# NPCX498S register map
File version: 1.0
Registers are 8-bit, read-write, reset 0x0 unless marked. A register's access mark holds for its fields unless they carry their own. Offsets are from the block's base; [hi:lo] are bit positions; {n}, {i} and the like mark numbered series; 'fields as' and 'values as' point back to an identical list.

## ESPI
Base 0x4000A000
0x00 ESPIID 32-bit — eSPI Identification Register (ESPIID)
  [7:0] ID — Host Version ID
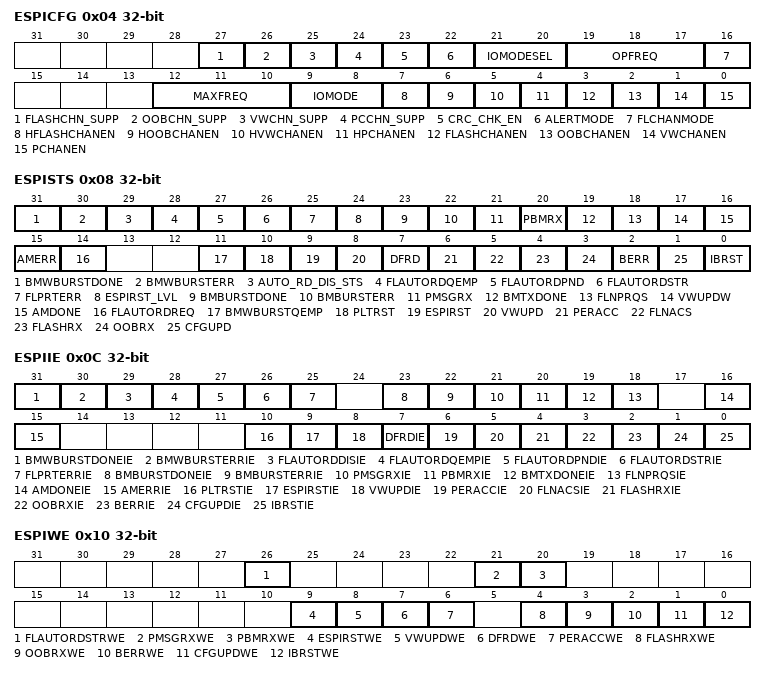
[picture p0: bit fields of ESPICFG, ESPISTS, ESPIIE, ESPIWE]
0x04 ESPICFG 32-bit (reset mask 0xFF) — eSPI Configuration Register (ESPICFG)
  [27] FLASHCHN_SUPP — Flash Access Channel Supported
  [26] OOBCHN_SUPP — OOB Channel Supported
  [25] VWCHN_SUPP — Virtual Wire Channel Supported
  [24] PCCHN_SUPP — Peripheral Channel Supported
  [23] CRC_CHK_EN — CRC Checking Enable
  [22] ALERTMODE
  [21:20] IOMODESEL — I/O Mode Select
  [19:17] OPFREQ — Operating Frequency
  [16] FLCHANMODE — Flash Access Channel Mode
  [12:10] MAXFREQ — Maximum Frequency Supported
  [9:8] IOMODE — I/O mode support
  [7] HFLASHCHANEN — Host Flash Access Channel Enable
  [6] HOOBCHANEN — Host OOB Channel Enable
  [5] HVWCHANEN — Host Virtual Wire Channel Enable
  [4] HPCHANEN — Host Peripheral Channel Enable
  [3] FLASHCHANEN — Core Flash Access Channel Enable
  [2] OOBCHANEN — Core OOB Channel Enable
  [1] VWCHANEN — Core Virtual Wire Channel Enable
  [0] PCHANEN — Core Peripheral Channel Enable
0x08 ESPISTS 32-bit (reset mask 0xFF) — eSPI Status Register (ESPISTS)
  [31] BMWBURSTDONE — Bus Master Burst Mode Write Transfer Done
  [30] BMWBURSTERR — Bus Master Burst Mode Write Transfer Error
  [29] AUTO_RD_DIS_STS — Automatic Read Disable Status
  [28] FLAUTORDQEMP — Flash Automatic Read Queue Empty
  [27] FLAUTORDPND — Flash Automatic Read Request Pending
  [26] FLAUTORDSTR — Flash Automatic Read Request Start
  [25] FLPRTERR — Flash Protection Error
  [24] ESPIRST_LVL — eSPI_RST Level
  [23] BMBURSTDONE — Bus Master Burst Mode Read Transfer Done
  [22] BMBURSTERR — Bus Master Burst Mode Read Transfer Error
  [21] PMSGRX — Peripheral Message Data Received
  [20] PBMRX — Peripheral Bus Master Data Received
  [19] BMTXDONE — Peripheral Bus Master Data Transmitted
  [18] FLNPRQS — Flash Non-Posted Request Sent
  [17] VWUPDW — Virtual Wire Updated Wake-Up
  [16] AMDONE — Automatic Mode Transfer Done
  [15] AMERR — Automatic Mode Transfer Error
  [14] FLAUTORDREQ — Flash Automatic Read Request
  [11] BMWBURSTQEMP — Bus Master Burst Mode Write Queue Empty
  [10] PLTRST — PLTRST Activated
  [9] ESPIRST — eSPI_RST Activated
  [8] VWUPD — Virtual Wire Updated
  [7] DFRD — Peripheral Channel Transaction Deferred
  [6] PERACC — Peripheral Channel Access Detected
  [5] FLNACS — Flash Non-Automatic Completion Sent
  [4] FLASHRX — Flash Data Received
  [3] OOBRX — OOB Data Received
  [2] BERR — eSPI Bus Error
  [1] CFGUPD — eSPI Configuration Updated
  [0] IBRST — In-Band Reset Command Received
0x0C ESPIIE 32-bit (reset mask 0xFF) — eSPI Interrupt Enable Register (ESPIIE)
  [31] BMWBURSTDONEIE — BMWBURSTDONE Interrupt Enable
  [30] BMWBURSTERRIE — BMWRBURSTERR Interrupt Enable
  [29] FLAUTORDDISIE — AUTO_RD_DIS_STS Interrupt Enable
  [28] FLAUTORDQEMPIE — FLAUTORDQEMP Interrupt Enable
  [27] FLAUTORDPNDIE — FLAUTORDPND Interrupt Enable
  [26] FLAUTORDSTRIE — FLAUTORDSTR Interrupt Enable
  [25] FLPRTERRIE — FLPRTERR Interrupt Enable
  [23] BMBURSTDONEIE — BMBURSTDONE Interrupt Enable
  [22] BMBURSTERRIE — BMBURSTERR Interrupt Enable
  [21] PMSGRXIE — PMSGRX Interrupt Enable
  [20] PBMRXIE — PBMRX Interrupt Enable
  [19] BMTXDONEIE — BMTXDONE Interrupt Enable
  [18] FLNPRQSIE — FLNPRQS Interrupt Enable
  [16] AMDONEIE — AMDONE Interrupt Enable
  [15] AMERRIE — AMERR Interrupt Enable
  [10] PLTRSTIE — PLTRST Interrupt Enable
  [9] ESPIRSTIE — eSPI_RST Interrupt Enable
  [8] VWUPDIE — VWUPD Interrupt Enable
  [7] DFRDIE — DFRD Interrupt Enable
  [6] PERACCIE — PERACC Interrupt Enable
  [5] FLNACSIE — FLNACS Interrupt Enable
  [4] FLASHRXIE — FLASHRX Interrupt Enable
  [3] OOBRXIE — OOBRX Interrupt Enable
  [2] BERRIE — BERR Interrupt Enable
  [1] CFGUPDIE — CFGUPD Interrupt Enable
  [0] IBRSTIE — IBRST Interrupt Enable
0x10 ESPIWE 32-bit (reset mask 0xFF) — eSPI Wake-Up Enable Register (ESPIWE)
  [26] FLAUTORDSTRWE — FLAUTORDSTR Wake-Up Enable
  [21] PMSGRXWE — PMSGRX Wake-Up Enable
  [20] PBMRXWE — PBMRX Wake-Up Enable
  [9] ESPIRSTWE — eSPI_RST Wake-Up Enable
  [8] VWUPDWE — VWUPD Wake-Up Enable
  [7] DFRDWE — DFRD Wake-Up Enable
  [6] PERACCWE — PERACC Wake-Up Enable
  [4] FLASHRXWE — FLASHRX Wake-Up Enable
  [3] OOBRXWE — OOBRX Wake-Up Enable
  [2] BERRWE — BERR Wake-Up Enable
  [1] CFGUPDWE — CFGUPD Wake-Up Enable
  [0] IBRSTWE — IBRST Wake-Up Enable
0x14 VWREGIDX 32-bit (reset mask 0xFF) — Virtual Wire Register Index Register (VWREGIDX)
  [11:2] VWREGIDX — Virtual Wire Register Index
0x18 VWREGDATA 32-bit (reset mask 0xFF) — Virtual Wire Register Data Register (VWREGDATA)
0x1C OOBRXRDHEAD 32-bit (reset mask 0xFF) — OOB Receive Buffer Read Head Register (OOBRXRDHEAD)
0x20 OOBTXWRHEAD 32-bit (reset mask 0xFF) — OOB Transmit Buffer Write Head Register (OOBTXWRHEAD)
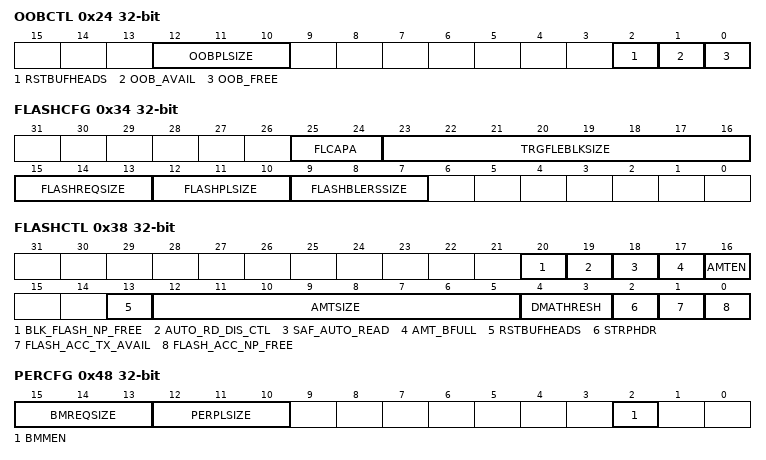
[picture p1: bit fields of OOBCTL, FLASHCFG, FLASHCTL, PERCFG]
0x24 OOBCTL 32-bit (reset mask 0xFF) — OOB Channel Control Register (OOBCTL)
  [12:10] OOBPLSIZE — OOB Channel Maximum Payload Size
  [2] RSTBUFHEADS — Reset Buffer Heads
  [1] OOB_AVAIL — OOB Transmit Queue Available
  [0] OOB_FREE — OOB Receive Queue Free
0x28 FLASHRXRDHEAD 32-bit (reset mask 0xFF) — Flash Receive Buffer Read Head Register (FLASHRXRDHEAD)
0x2C FLASHTXWRHEAD 32-bit (reset mask 0xFF) — Flash Transmit Buffer Write Head Register (FLASHTXWRHEAD)
0x34 FLASHCFG 32-bit (reset mask 0xFF) — Flash Channel Configuration Register (FLASHCFG)
  [25:24] FLCAPA — Flash Sharing Capability Support
  [23:16] TRGFLEBLKSIZE — Target Flash Erase Block Size
  [15:13] FLASHREQSIZE — Flash Access Channel Maximum Read Request Size
  [12:10] FLASHPLSIZE — Flash Access Channel Maximum Payload Size
  [9:7] FLASHBLERSSIZE — Flash Access Channel Block Erase Size
0x38 FLASHCTL 32-bit (reset mask 0xFF) — Flash Channel Control Register (FLASHCTL)
  [20] BLK_FLASH_NP_FREE — Block FLASH_NP_FREE
  [19] AUTO_RD_DIS_CTL — Disable Automatic Read Control
  [18] SAF_AUTO_READ — Target-Attached Flash Automatic Read
  [17] AMT_BFULL — Automatic Mode Receive Buffer Full
  [16] AMTEN — Automatic Mode Enable
  [13] RSTBUFHEADS — Reset Buffer Heads
  [12:5] AMTSIZE — Automatic Mode Transfer Size
  [4:3] DMATHRESH — DMA Request Threshold
  [2] STRPHDR — Strip Header
  [1] FLASH_ACC_TX_AVAIL — Flash Access Transmit Queue Available
  [0] FLASH_ACC_NP_FREE — Flash Access Non-Posted Queue Free
0x3C ESPIERR 32-bit (reset mask 0xFF) — eSPI Error Status Register (ESPIERR)
  [15] UNFLASH — Unsuccessful Flash Completion
  [14] UNPBM — Unsuccessful Bus Master Completion
  [10] VWERR — Virtual Channel Access Error
  [10] EXTRACYC — Extra eSPI Clock Cycles
  [9] UNCMD — Unsupported Command or Cycle Type
  [8] FLBADALN — Target-Attached Flash Bad Address Alignment
  [7] PCBADALN — Posted Peripheral Channel Bad Address Alignment
  [6] NPBADALN — Non-Posted Peripheral Channel Bad Address Alignment
  [5] BADSIZE
  [4] PROTERR — Protocol Error
  [3] ABCOMP — Abnormal Completion
  [2] CRCERR — Transaction CRC Error
  [1] INVCYC — Invalid Cycle Type
  [0] INVCMD — Invalid Command Type
0x40 PBMRXRDHEAD 32-bit (reset mask 0xFF) — Peripheral Bus Master Receive Buffer Read Head Register (PBMRXRDHEAD)
0x44 PBMTXWRHEAD 32-bit (reset mask 0xFF) — Peripheral Bus Master Transmit Buffer Write Head Register (PBMTXWRHEAD)
0x48 PERCFG 32-bit (reset mask 0xFF) — Peripheral Channel Configuration Register (PERCFG)
  [15:13] BMREQSIZE — Peripheral Channel Maximum Read Request Size
  [12:10] PERPLSIZE — Peripheral Channel Maximum Payload Size
  [2] BMMEN — Bus Master Enable
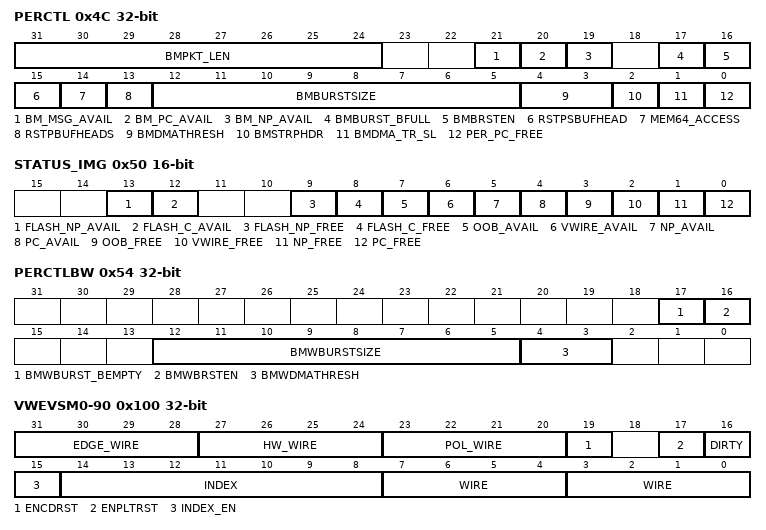
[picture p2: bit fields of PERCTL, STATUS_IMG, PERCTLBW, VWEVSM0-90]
0x4C PERCTL 32-bit (reset mask 0xFF) — Peripheral Channel Control Register (PERCTL)
  [31:24] BMPKT_LEN — Bus Master Packet Length
  [21] BM_MSG_AVAIL — Bus Master Message Available
  [20] BM_PC_AVAIL — Bus Master Posted Available
  [19] BM_NP_AVAIL — Bus Master Non-Posted Available
  [17] BMBURST_BFULL — Bus Master Burst Mode Read Receive Buffer Full
  [16] BMBRSTEN — Bus Master Burst Mode Read Enable
  [15] RSTPSBUFHEAD — Reset Peripheral Target Buffer Head
  [14] MEM64_ACCESS — Memory 64-Bit Access Select
  [13] RSTPBUFHEADS — Reset Peripheral Buffer Heads
  [12:5] BMBURSTSIZE — Bus Master Burst Mode Read Transfer Size
  [4:3] BMDMATHRESH — Read Bus Master DMA Request Threshold
  [2] BMSTRPHDR — Read Bus Master Strip Header
  [1] BMDMA_TR_SL — Bus Master DMA Transmit/Receive Select
  [0] PER_PC_FREE — Peripheral Channel Posted/Completion Receive Queue Free
0x50 STATUS_IMG 16-bit (reset mask 0xFF) — Status Image Register (STATUS_IMG)
  [13] FLASH_NP_AVAIL — Flash Channel Non-Posted Transmit Available
  [12] FLASH_C_AVAIL — Flash Channel Completion Transmit Available
  [9] FLASH_NP_FREE — Flash Channel Non-Posted Receive Free
  [8] FLASH_C_FREE — Flash Channel Completion Receive Available
  [7] OOB_AVAIL — OOB Channel Posted Transmit. Available
  [6] VWIRE_AVAIL — Virtual Wire Channel Transmit Available
  [5] NP_AVAIL — Peripheral Channel Non-Posted Transmit Available
  [4] PC_AVAIL — Peripheral Channel Posted/Completion Transmit. Available
  [3] OOB_FREE — OOB Channel Posted Receive Free
  [2] VWIRE_FREE — Virtual Wire Channel Receive Free
  [1] NP_FREE — Peripheral Channel Non-Posted Receive. Free
  [0] PC_FREE — Peripheral Channel Posted Receive Free
0x54 PERCTLBW 32-bit (reset mask 0xFF) — Peripheral Channel Control for Bus Master Write Register (PERCTLBW)
  [17] BMWBURST_BEMPTY — Bus Master Burst Mode Write Transmit Buffer Empty
  [16] BMWBRSTEN — Bus Master Burst Mode Write Enable
  [12:5] BMWBURSTSIZE — Bus Master Burst Mode Write Transfer Size
  [4:3] BMWDMATHRESH — Bus Master Write DMA Request Threshold
0x58 PSMRXRDHEAD 32-bit (reset mask 0xFF) — Peripheral Target Message Receive Buffer Read Head Register (PSMRXRDHEAD)
0x100 VWEVSM0-90 32-bit (reset mask 0xFF) — Virtual Wire Event Target-to-Controller Register 0-9 (VWEVSM0-9)
  [31:28] EDGE_WIRE 3_0 — Edge Type Wire 3-0
  [27:24] HW_WIRE 3_0 — Hardware-Controlled Wire 3-0
  [23:20] POL_WIRE 3_0 — Polarity of Wire 3-0
  [19] ENCDRST — Enable Core Reset
  [17] ENPLTRST — Enable PLTRST
  [16] DIRTY
  [15] INDEX_EN — Index Enable
  [14:8] INDEX — Index Value
  [7:4] WIRE 3_0 VALID
  [3:0] WIRE 3_0
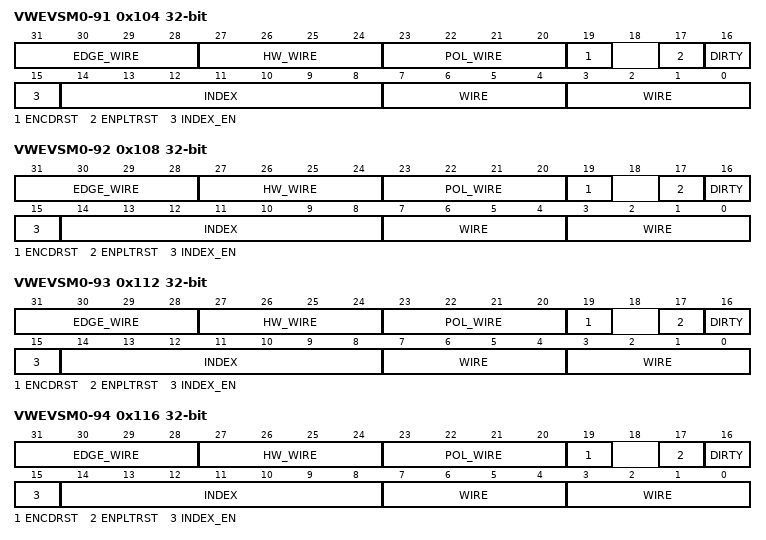
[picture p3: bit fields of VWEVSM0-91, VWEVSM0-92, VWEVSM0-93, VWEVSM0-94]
0x104 VWEVSM0-91 32-bit (reset mask 0xFF) — Virtual Wire Event Target-to-Controller Register 0-9 (VWEVSM0-9)
  fields as VWEVSM0-90
0x108 VWEVSM0-92 32-bit (reset mask 0xFF) — Virtual Wire Event Target-to-Controller Register 0-9 (VWEVSM0-9)
  fields as VWEVSM0-90
0x112 VWEVSM0-93 32-bit (reset mask 0xFF) — Virtual Wire Event Target-to-Controller Register 0-9 (VWEVSM0-9)
  fields as VWEVSM0-90
0x116 VWEVSM0-94 32-bit (reset mask 0xFF) — Virtual Wire Event Target-to-Controller Register 0-9 (VWEVSM0-9)
  fields as VWEVSM0-90
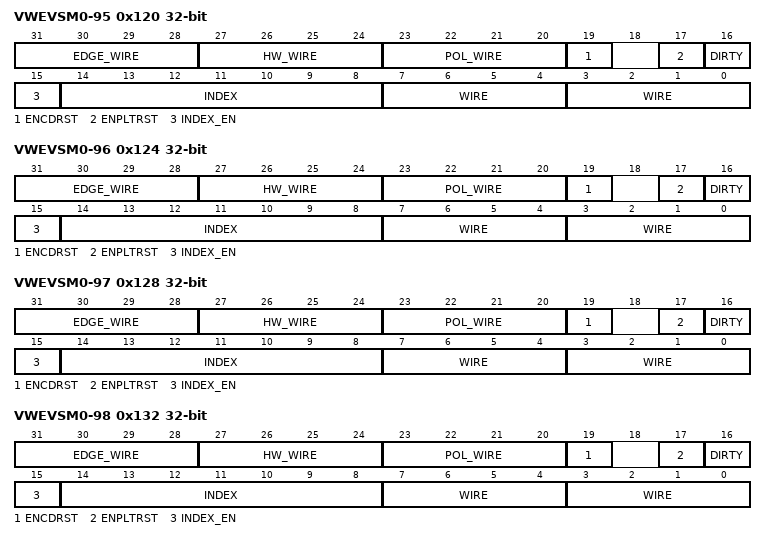
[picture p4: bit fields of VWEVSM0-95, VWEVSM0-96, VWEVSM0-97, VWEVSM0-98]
0x120 VWEVSM0-95 32-bit (reset mask 0xFF) — Virtual Wire Event Target-to-Controller Register 0-9 (VWEVSM0-9)
  fields as VWEVSM0-90
0x124 VWEVSM0-96 32-bit (reset mask 0xFF) — Virtual Wire Event Target-to-Controller Register 0-9 (VWEVSM0-9)
  fields as VWEVSM0-90
0x128 VWEVSM0-97 32-bit (reset mask 0xFF) — Virtual Wire Event Target-to-Controller Register 0-9 (VWEVSM0-9)
  fields as VWEVSM0-90
0x132 VWEVSM0-98 32-bit (reset mask 0xFF) — Virtual Wire Event Target-to-Controller Register 0-9 (VWEVSM0-9)
  fields as VWEVSM0-90
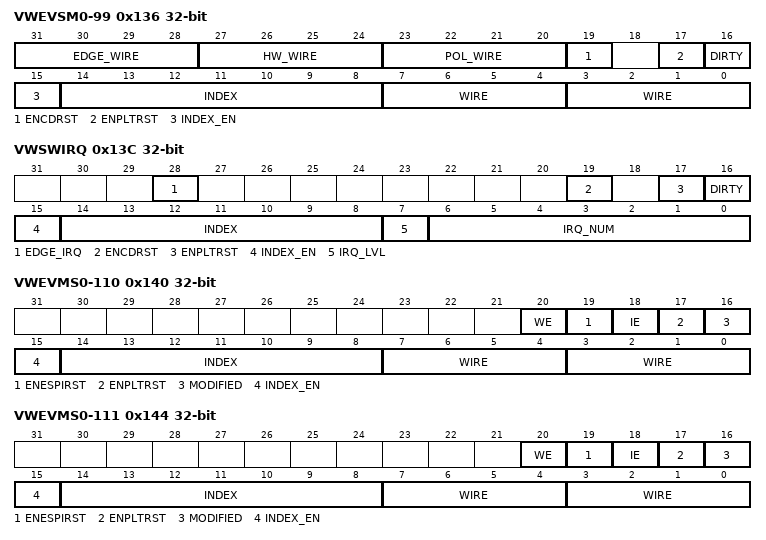
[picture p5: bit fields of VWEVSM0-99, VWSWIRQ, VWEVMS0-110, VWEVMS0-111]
0x136 VWEVSM0-99 32-bit (reset mask 0xFF) — Virtual Wire Event Target-to-Controller Register 0-9 (VWEVSM0-9)
  fields as VWEVSM0-90
0x13C VWSWIRQ 32-bit (reset mask 0xFF) — Virtual Wire Software IRQ Register (VWSWIRQ)
  [28] EDGE_IRQ — Edge Type IRQ
  [19] ENCDRST — Enable Core Reset
  [17] ENPLTRST — Enable PLTRST
  [16] DIRTY
  [15] INDEX_EN — Index Enable
  [14:8] INDEX — Index Value
  [7] IRQ_LVL — IRQ Level
  [6:0] IRQ_NUM — IRQ Number
0x140 VWEVMS0-110 32-bit (reset mask 0xFF) — Virtual Wire Event Controller-to-Target Register 0-11 (VWEVMS0-11)
  [20] WE — Wake-up Enable
  [19] ENESPIRST — Enable eSPI_RST
  [18] IE — Interrupt Enable
  [17] ENPLTRST — Enable PLTRST
  [16] MODIFIED
  [15] INDEX_EN — Index Enable
  [14:8] INDEX — Index Value
  [7:4] WIRE 3_0 VALID
  [3:0] WIRE 3_0
0x144 VWEVMS0-111 32-bit (reset mask 0xFF) — Virtual Wire Event Controller-to-Target Register 0-11 (VWEVMS0-11)
  fields as VWEVMS0-110
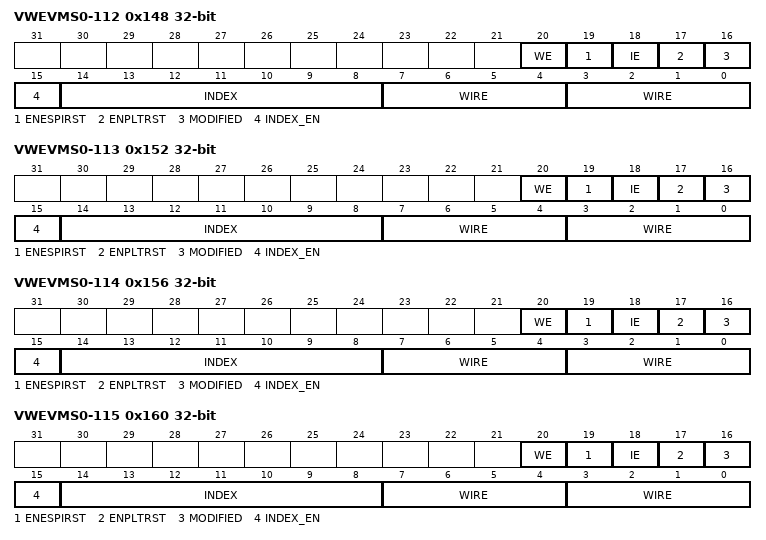
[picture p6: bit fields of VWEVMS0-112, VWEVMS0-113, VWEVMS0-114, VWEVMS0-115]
0x148 VWEVMS0-112 32-bit (reset mask 0xFF) — Virtual Wire Event Controller-to-Target Register 0-11 (VWEVMS0-11)
  fields as VWEVMS0-110
0x152 VWEVMS0-113 32-bit (reset mask 0xFF) — Virtual Wire Event Controller-to-Target Register 0-11 (VWEVMS0-11)
  fields as VWEVMS0-110
0x156 VWEVMS0-114 32-bit (reset mask 0xFF) — Virtual Wire Event Controller-to-Target Register 0-11 (VWEVMS0-11)
  fields as VWEVMS0-110
0x160 VWEVMS0-115 32-bit (reset mask 0xFF) — Virtual Wire Event Controller-to-Target Register 0-11 (VWEVMS0-11)
  fields as VWEVMS0-110
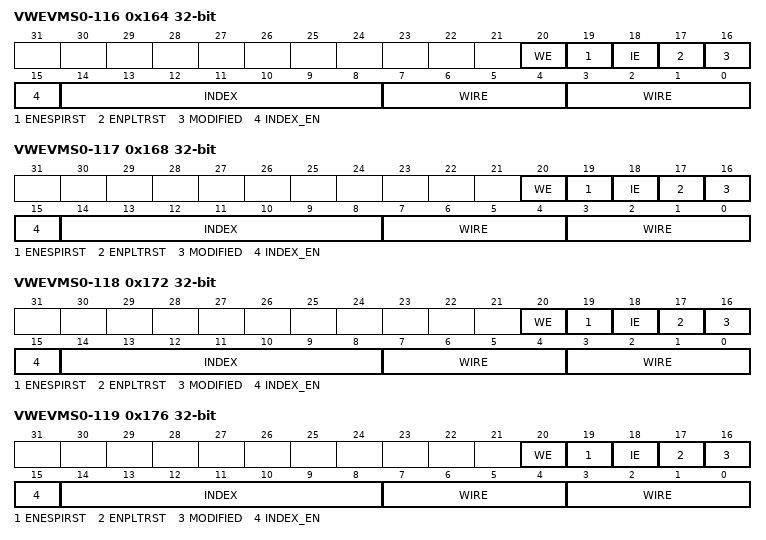
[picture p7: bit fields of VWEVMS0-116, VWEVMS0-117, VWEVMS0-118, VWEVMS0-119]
0x164 VWEVMS0-116 32-bit (reset mask 0xFF) — Virtual Wire Event Controller-to-Target Register 0-11 (VWEVMS0-11)
  fields as VWEVMS0-110
0x168 VWEVMS0-117 32-bit (reset mask 0xFF) — Virtual Wire Event Controller-to-Target Register 0-11 (VWEVMS0-11)
  fields as VWEVMS0-110
0x172 VWEVMS0-118 32-bit (reset mask 0xFF) — Virtual Wire Event Controller-to-Target Register 0-11 (VWEVMS0-11)
  fields as VWEVMS0-110
0x176 VWEVMS0-119 32-bit (reset mask 0xFF) — Virtual Wire Event Controller-to-Target Register 0-11 (VWEVMS0-11)
  fields as VWEVMS0-110
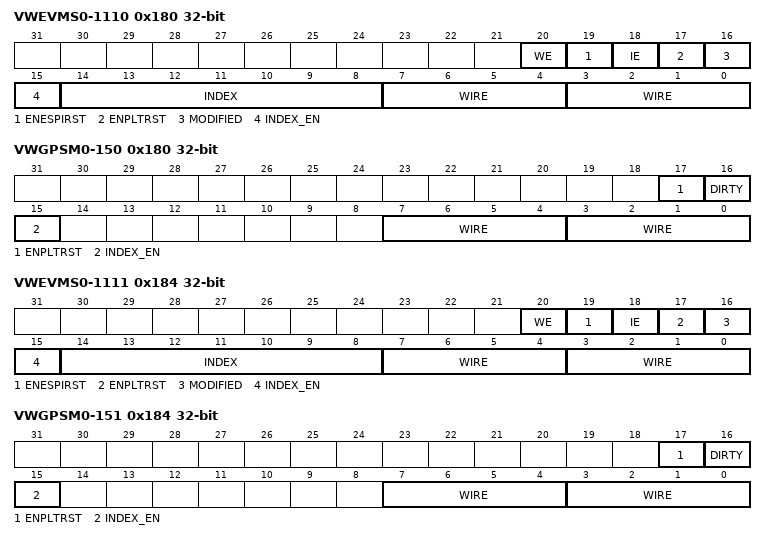
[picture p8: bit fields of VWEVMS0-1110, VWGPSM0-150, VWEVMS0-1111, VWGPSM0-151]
0x180 VWEVMS0-1110 32-bit (reset mask 0xFF) — Virtual Wire Event Controller-to-Target Register 0-11 (VWEVMS0-11)
  fields as VWEVMS0-110
0x180 VWGPSM0-150 32-bit (reset mask 0xFF) — Virtual Wire GPIO Target-to-Controller Register 0-15 (VWGPSM0-15)
  [17] ENPLTRST — Enable PLTRST
  [16] DIRTY
  [15] INDEX_EN — Index Enable
  [7:4] WIRE 3_0 VALID
  [3:0] WIRE 3_0
0x184 VWEVMS0-1111 32-bit (reset mask 0xFF) — Virtual Wire Event Controller-to-Target Register 0-11 (VWEVMS0-11)
  fields as VWEVMS0-110
0x184 VWGPSM0-151 32-bit (reset mask 0xFF) — Virtual Wire GPIO Target-to-Controller Register 0-15 (VWGPSM0-15)
  fields as VWGPSM0-150
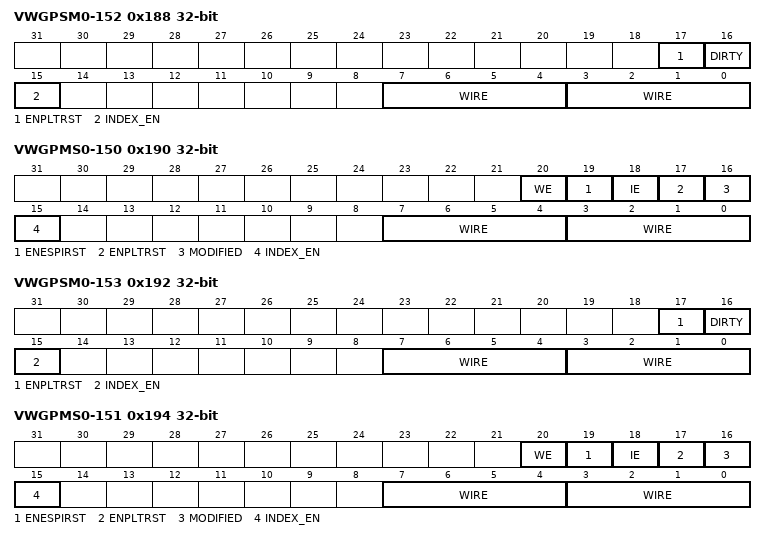
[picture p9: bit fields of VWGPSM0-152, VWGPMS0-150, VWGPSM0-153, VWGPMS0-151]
0x188 VWGPSM0-152 32-bit (reset mask 0xFF) — Virtual Wire GPIO Target-to-Controller Register 0-15 (VWGPSM0-15)
  fields as VWGPSM0-150
0x190 VWGPMS0-150 32-bit (reset mask 0xFF) — Virtual Wire GPIO Controller-to-Target Register 0-15 (VWGPMS0-15)
  [20] WE — Wake-up Enable
  [19] ENESPIRST — Enable eSPI_RST
  [18] IE — Interrupt Enable
  [17] ENPLTRST — Enable PLTRST
  [16] MODIFIED
  [15] INDEX_EN — Index Enable
  [7:4] WIRE 3_0 VALID
  [3:0] WIRE 3_0
0x192 VWGPSM0-153 32-bit (reset mask 0xFF) — Virtual Wire GPIO Target-to-Controller Register 0-15 (VWGPSM0-15)
  fields as VWGPSM0-150
0x194 VWGPMS0-151 32-bit (reset mask 0xFF) — Virtual Wire GPIO Controller-to-Target Register 0-15 (VWGPMS0-15)
  fields as VWGPMS0-150
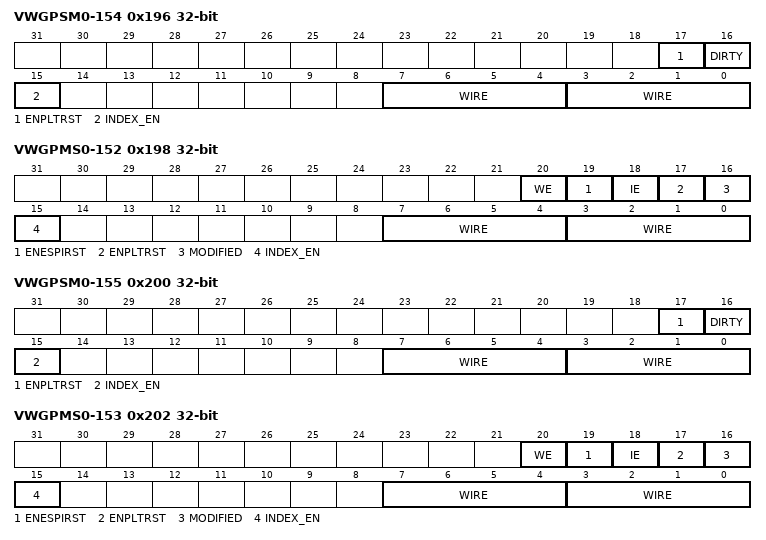
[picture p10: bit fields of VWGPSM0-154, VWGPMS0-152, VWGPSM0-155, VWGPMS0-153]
0x196 VWGPSM0-154 32-bit (reset mask 0xFF) — Virtual Wire GPIO Target-to-Controller Register 0-15 (VWGPSM0-15)
  fields as VWGPSM0-150
0x198 VWGPMS0-152 32-bit (reset mask 0xFF) — Virtual Wire GPIO Controller-to-Target Register 0-15 (VWGPMS0-15)
  fields as VWGPMS0-150
0x200 VWGPSM0-155 32-bit (reset mask 0xFF) — Virtual Wire GPIO Target-to-Controller Register 0-15 (VWGPSM0-15)
  fields as VWGPSM0-150
0x202 VWGPMS0-153 32-bit (reset mask 0xFF) — Virtual Wire GPIO Controller-to-Target Register 0-15 (VWGPMS0-15)
  fields as VWGPMS0-150
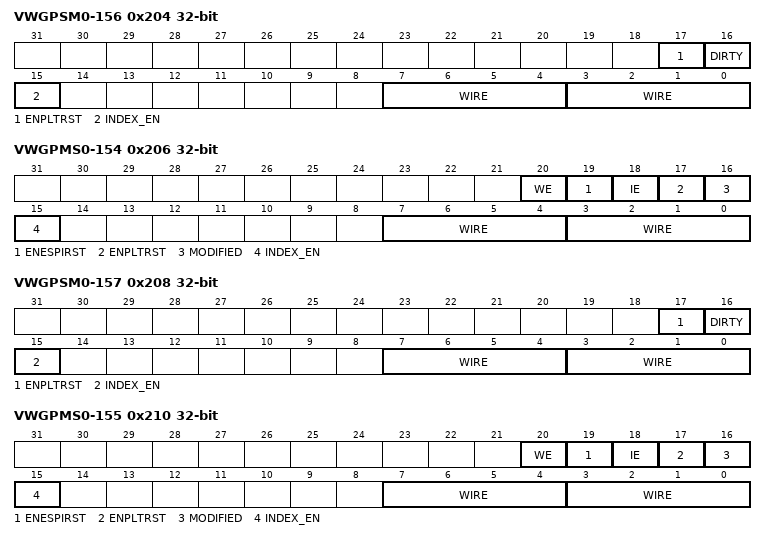
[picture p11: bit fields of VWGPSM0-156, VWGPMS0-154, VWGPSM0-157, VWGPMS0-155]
0x204 VWGPSM0-156 32-bit (reset mask 0xFF) — Virtual Wire GPIO Target-to-Controller Register 0-15 (VWGPSM0-15)
  fields as VWGPSM0-150
0x206 VWGPMS0-154 32-bit (reset mask 0xFF) — Virtual Wire GPIO Controller-to-Target Register 0-15 (VWGPMS0-15)
  fields as VWGPMS0-150
0x208 VWGPSM0-157 32-bit (reset mask 0xFF) — Virtual Wire GPIO Target-to-Controller Register 0-15 (VWGPSM0-15)
  fields as VWGPSM0-150
0x210 VWGPMS0-155 32-bit (reset mask 0xFF) — Virtual Wire GPIO Controller-to-Target Register 0-15 (VWGPMS0-15)
  fields as VWGPMS0-150
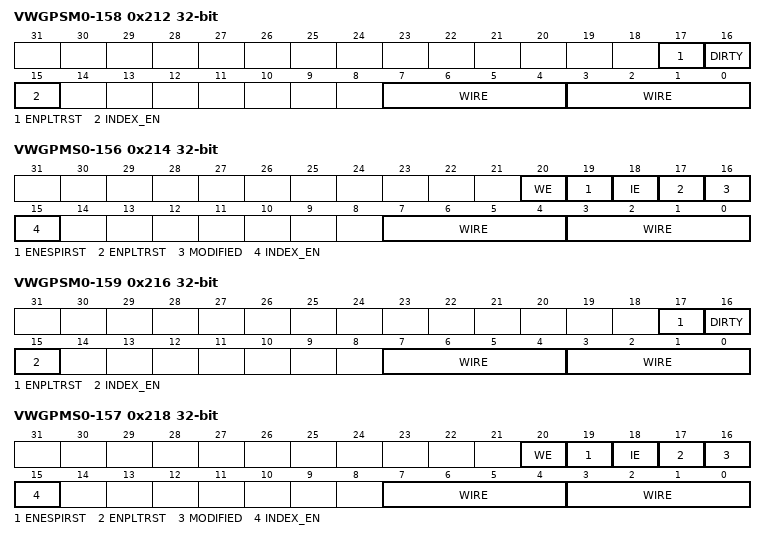
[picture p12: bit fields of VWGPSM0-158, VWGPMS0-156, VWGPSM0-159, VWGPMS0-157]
0x212 VWGPSM0-158 32-bit (reset mask 0xFF) — Virtual Wire GPIO Target-to-Controller Register 0-15 (VWGPSM0-15)
  fields as VWGPSM0-150
0x214 VWGPMS0-156 32-bit (reset mask 0xFF) — Virtual Wire GPIO Controller-to-Target Register 0-15 (VWGPMS0-15)
  fields as VWGPMS0-150
0x216 VWGPSM0-159 32-bit (reset mask 0xFF) — Virtual Wire GPIO Target-to-Controller Register 0-15 (VWGPSM0-15)
  fields as VWGPSM0-150
0x218 VWGPMS0-157 32-bit (reset mask 0xFF) — Virtual Wire GPIO Controller-to-Target Register 0-15 (VWGPMS0-15)
  fields as VWGPMS0-150
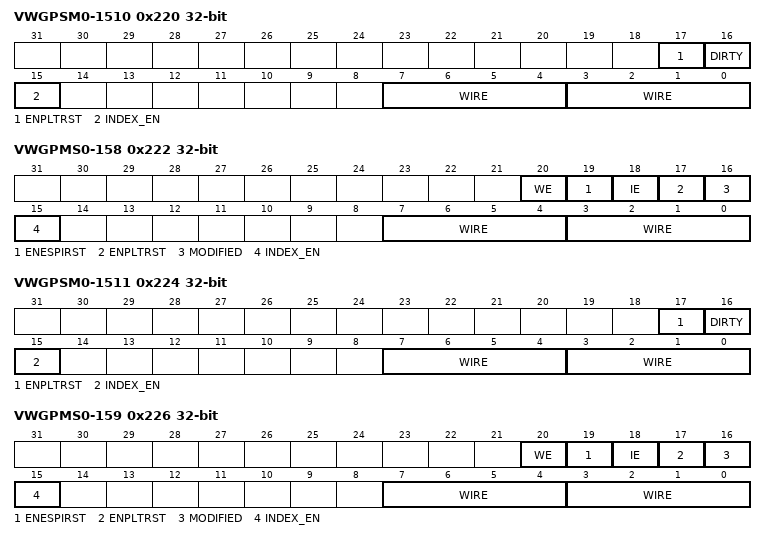
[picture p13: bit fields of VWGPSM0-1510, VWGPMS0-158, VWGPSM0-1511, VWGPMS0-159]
0x220 VWGPSM0-1510 32-bit (reset mask 0xFF) — Virtual Wire GPIO Target-to-Controller Register 0-15 (VWGPSM0-15)
  fields as VWGPSM0-150
0x222 VWGPMS0-158 32-bit (reset mask 0xFF) — Virtual Wire GPIO Controller-to-Target Register 0-15 (VWGPMS0-15)
  fields as VWGPMS0-150
0x224 VWGPSM0-1511 32-bit (reset mask 0xFF) — Virtual Wire GPIO Target-to-Controller Register 0-15 (VWGPSM0-15)
  fields as VWGPSM0-150
0x226 VWGPMS0-159 32-bit (reset mask 0xFF) — Virtual Wire GPIO Controller-to-Target Register 0-15 (VWGPMS0-15)
  fields as VWGPMS0-150
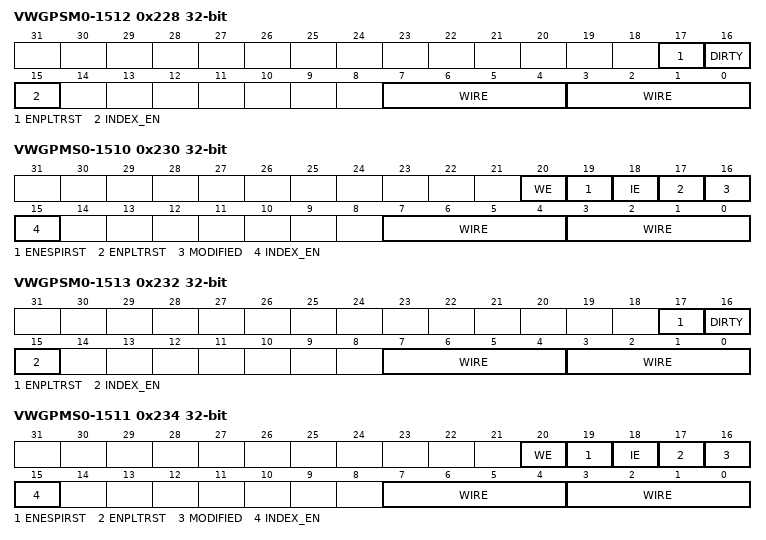
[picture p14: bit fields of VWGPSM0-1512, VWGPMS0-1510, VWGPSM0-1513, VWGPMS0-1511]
0x228 VWGPSM0-1512 32-bit (reset mask 0xFF) — Virtual Wire GPIO Target-to-Controller Register 0-15 (VWGPSM0-15)
  fields as VWGPSM0-150
0x230 VWGPMS0-1510 32-bit (reset mask 0xFF) — Virtual Wire GPIO Controller-to-Target Register 0-15 (VWGPMS0-15)
  fields as VWGPMS0-150
0x232 VWGPSM0-1513 32-bit (reset mask 0xFF) — Virtual Wire GPIO Target-to-Controller Register 0-15 (VWGPSM0-15)
  fields as VWGPSM0-150
0x234 VWGPMS0-1511 32-bit (reset mask 0xFF) — Virtual Wire GPIO Controller-to-Target Register 0-15 (VWGPMS0-15)
  fields as VWGPMS0-150
0x236 VWGPSM0-1514 32-bit (reset mask 0xFF) — Virtual Wire GPIO Target-to-Controller Register 0-15 (VWGPSM0-15)
  fields as VWGPSM0-150
0x238 VWGPMS0-1512 32-bit (reset mask 0xFF) — Virtual Wire GPIO Controller-to-Target Register 0-15 (VWGPMS0-15)
  fields as VWGPMS0-150
0x240 VWGPSM0-1515 32-bit (reset mask 0xFF) — Virtual Wire GPIO Target-to-Controller Register 0-15 (VWGPSM0-15)
  fields as VWGPSM0-150
0x242 VWGPMS0-1513 32-bit (reset mask 0xFF) — Virtual Wire GPIO Controller-to-Target Register 0-15 (VWGPMS0-15)
  fields as VWGPMS0-150
0x246 VWGPMS0-1514 32-bit (reset mask 0xFF) — Virtual Wire GPIO Controller-to-Target Register 0-15 (VWGPMS0-15)
  fields as VWGPMS0-150
0x250 VWGPMS0-1515 32-bit (reset mask 0xFF) — Virtual Wire GPIO Controller-to-Target Register 0-15 (VWGPMS0-15)
  fields as VWGPMS0-150
0x2FC VWCTL 32-bit — Virtual Wire Channel Control Register (VWCTL)
  [5] NO_VALID — No Valid Bits
  [4] IRQ_DIS — IRQ Deassert
  [3:2] GPVWMAP — GPIO Virtual Wire Indices Mapping
  [1:0] INTWIN — Interrupt Window Select
{0x8+4i} OOBRXBUF0-{i} 32-bit (reset mask 0xFF) (i=190..192) — OOB Receive Buffer Register 0-19 (OOBRXBUF0-19)
0x312 OOBRXBUF0-193 32-bit (reset mask 0xFF) — OOB Receive Buffer Register 0-19 (OOBRXBUF0-19)
0x316 OOBRXBUF0-194 32-bit (reset mask 0xFF) — OOB Receive Buffer Register 0-19 (OOBRXBUF0-19)
{0x14+4i} OOBRXBUF0-{i} 32-bit (reset mask 0xFF) (i=195..197) — OOB Receive Buffer Register 0-19 (OOBRXBUF0-19)
0x332 OOBRXBUF0-198 32-bit (reset mask 0xFF) — OOB Receive Buffer Register 0-19 (OOBRXBUF0-19)
0x336 OOBRXBUF0-199 32-bit (reset mask 0xFF) — OOB Receive Buffer Register 0-19 (OOBRXBUF0-19)
0x340 OOBRXBUF0-1910 32-bit (reset mask 0xFF) — OOB Receive Buffer Register 0-19 (OOBRXBUF0-19)
0x344 OOBRXBUF0-1911 32-bit (reset mask 0xFF) — OOB Receive Buffer Register 0-19 (OOBRXBUF0-19)
0x348 OOBRXBUF0-1912 32-bit (reset mask 0xFF) — OOB Receive Buffer Register 0-19 (OOBRXBUF0-19)
0x352 OOBRXBUF0-1913 32-bit (reset mask 0xFF) — OOB Receive Buffer Register 0-19 (OOBRXBUF0-19)
0x356 OOBRXBUF0-1914 32-bit (reset mask 0xFF) — OOB Receive Buffer Register 0-19 (OOBRXBUF0-19)
0x360 OOBRXBUF0-1915 32-bit (reset mask 0xFF) — OOB Receive Buffer Register 0-19 (OOBRXBUF0-19)
0x364 OOBRXBUF0-1916 32-bit (reset mask 0xFF) — OOB Receive Buffer Register 0-19 (OOBRXBUF0-19)
0x368 OOBRXBUF0-1917 32-bit (reset mask 0xFF) — OOB Receive Buffer Register 0-19 (OOBRXBUF0-19)
0x372 OOBRXBUF0-1918 32-bit (reset mask 0xFF) — OOB Receive Buffer Register 0-19 (OOBRXBUF0-19)
0x376 OOBRXBUF0-1919 32-bit (reset mask 0xFF) — OOB Receive Buffer Register 0-19 (OOBRXBUF0-19)
{0x88+4i} OOBTXBUF0-{i} 32-bit (reset mask 0xFF) (i=190..192) — OOB Transmit Buffer Register 0-19 (OOBTXBUF0-19)
0x392 OOBTXBUF0-193 32-bit (reset mask 0xFF) — OOB Transmit Buffer Register 0-19 (OOBTXBUF0-19)
0x396 OOBTXBUF0-194 32-bit (reset mask 0xFF) — OOB Transmit Buffer Register 0-19 (OOBTXBUF0-19)
{0xF4+4i} OOBTXBUF0-{i} 32-bit (reset mask 0xFF) (i=195..197) — OOB Transmit Buffer Register 0-19 (OOBTXBUF0-19)
{0x158+4i} FLASHRXBUF0-{i} 32-bit (reset mask 0xFF) (i=170..172) — Flash Receive Buffer Register 0-17 (FLASHRXBUF0-17)
0x412 OOBTXBUF0-198 32-bit (reset mask 0xFF) — OOB Transmit Buffer Register 0-19 (OOBTXBUF0-19)
0x412 FLASHRXBUF0-173 32-bit (reset mask 0xFF) — Flash Receive Buffer Register 0-17 (FLASHRXBUF0-17)
0x416 OOBTXBUF0-199 32-bit (reset mask 0xFF) — OOB Transmit Buffer Register 0-19 (OOBTXBUF0-19)
0x416 FLASHRXBUF0-174 32-bit (reset mask 0xFF) — Flash Receive Buffer Register 0-17 (FLASHRXBUF0-17)
0x420 OOBTXBUF0-1910 32-bit (reset mask 0xFF) — OOB Transmit Buffer Register 0-19 (OOBTXBUF0-19)
{0x164+4i} FLASHRXBUF0-{i} 32-bit (reset mask 0xFF) (i=175..177) — Flash Receive Buffer Register 0-17 (FLASHRXBUF0-17)
0x424 OOBTXBUF0-1911 32-bit (reset mask 0xFF) — OOB Transmit Buffer Register 0-19 (OOBTXBUF0-19)
0x428 OOBTXBUF0-1912 32-bit (reset mask 0xFF) — OOB Transmit Buffer Register 0-19 (OOBTXBUF0-19)
0x432 OOBTXBUF0-1913 32-bit (reset mask 0xFF) — OOB Transmit Buffer Register 0-19 (OOBTXBUF0-19)
0x432 FLASHRXBUF0-178 32-bit (reset mask 0xFF) — Flash Receive Buffer Register 0-17 (FLASHRXBUF0-17)
0x436 OOBTXBUF0-1914 32-bit (reset mask 0xFF) — OOB Transmit Buffer Register 0-19 (OOBTXBUF0-19)
0x436 FLASHRXBUF0-179 32-bit (reset mask 0xFF) — Flash Receive Buffer Register 0-17 (FLASHRXBUF0-17)
0x440 OOBTXBUF0-1915 32-bit (reset mask 0xFF) — OOB Transmit Buffer Register 0-19 (OOBTXBUF0-19)
0x440 FLASHRXBUF0-1710 32-bit (reset mask 0xFF) — Flash Receive Buffer Register 0-17 (FLASHRXBUF0-17)
0x444 OOBTXBUF0-1916 32-bit (reset mask 0xFF) — OOB Transmit Buffer Register 0-19 (OOBTXBUF0-19)
0x444 FLASHRXBUF0-1711 32-bit (reset mask 0xFF) — Flash Receive Buffer Register 0-17 (FLASHRXBUF0-17)
0x448 OOBTXBUF0-1917 32-bit (reset mask 0xFF) — OOB Transmit Buffer Register 0-19 (OOBTXBUF0-19)
0x448 FLASHRXBUF0-1712 32-bit (reset mask 0xFF) — Flash Receive Buffer Register 0-17 (FLASHRXBUF0-17)
0x452 OOBTXBUF0-1918 32-bit (reset mask 0xFF) — OOB Transmit Buffer Register 0-19 (OOBTXBUF0-19)
0x452 FLASHRXBUF0-1713 32-bit (reset mask 0xFF) — Flash Receive Buffer Register 0-17 (FLASHRXBUF0-17)
0x456 OOBTXBUF0-1919 32-bit (reset mask 0xFF) — OOB Transmit Buffer Register 0-19 (OOBTXBUF0-19)
0x456 FLASHRXBUF0-1714 32-bit (reset mask 0xFF) — Flash Receive Buffer Register 0-17 (FLASHRXBUF0-17)
0x460 FLASHRXBUF0-1715 32-bit (reset mask 0xFF) — Flash Receive Buffer Register 0-17 (FLASHRXBUF0-17)
0x464 FLASHRXBUF0-1716 32-bit (reset mask 0xFF) — Flash Receive Buffer Register 0-17 (FLASHRXBUF0-17)
0x468 FLASHRXBUF0-1717 32-bit (reset mask 0xFF) — Flash Receive Buffer Register 0-17 (FLASHRXBUF0-17)
{0x200+4i} FLASHTXBUF0-{i} 32-bit (reset mask 0xFF) (i=160..162) — Flash Transmit Buffer Register 0-16 (FLASHTXBUF0-16)
0x492 FLASHTXBUF0-163 32-bit (reset mask 0xFF) — Flash Transmit Buffer Register 0-16 (FLASHTXBUF0-16)
0x496 FLASHTXBUF0-164 32-bit (reset mask 0xFF) — Flash Transmit Buffer Register 0-16 (FLASHTXBUF0-16)
{0x26C+4i} FLASHTXBUF0-{i} 32-bit (reset mask 0xFF) (i=165..167) — Flash Transmit Buffer Register 0-16 (FLASHTXBUF0-16)
{0x258+4i} PBMRXBUF0-{i} 32-bit (reset mask 0xFF) (i=170..172) — Peripheral Bus Master Receive Buffer Register 0-17 (PBMRXBUF0-17)
0x512 FLASHTXBUF0-168 32-bit (reset mask 0xFF) — Flash Transmit Buffer Register 0-16 (FLASHTXBUF0-16)
0x512 PBMRXBUF0-173 32-bit (reset mask 0xFF) — Peripheral Bus Master Receive Buffer Register 0-17 (PBMRXBUF0-17)
0x516 FLASHTXBUF0-169 32-bit (reset mask 0xFF) — Flash Transmit Buffer Register 0-16 (FLASHTXBUF0-16)
0x516 PBMRXBUF0-174 32-bit (reset mask 0xFF) — Peripheral Bus Master Receive Buffer Register 0-17 (PBMRXBUF0-17)
0x520 FLASHTXBUF0-1610 32-bit (reset mask 0xFF) — Flash Transmit Buffer Register 0-16 (FLASHTXBUF0-16)
{0x264+4i} PBMRXBUF0-{i} 32-bit (reset mask 0xFF) (i=175..177) — Peripheral Bus Master Receive Buffer Register 0-17 (PBMRXBUF0-17)
0x524 FLASHTXBUF0-1611 32-bit (reset mask 0xFF) — Flash Transmit Buffer Register 0-16 (FLASHTXBUF0-16)
0x528 FLASHTXBUF0-1612 32-bit (reset mask 0xFF) — Flash Transmit Buffer Register 0-16 (FLASHTXBUF0-16)
0x532 FLASHTXBUF0-1613 32-bit (reset mask 0xFF) — Flash Transmit Buffer Register 0-16 (FLASHTXBUF0-16)
0x532 PBMRXBUF0-178 32-bit (reset mask 0xFF) — Peripheral Bus Master Receive Buffer Register 0-17 (PBMRXBUF0-17)
0x536 FLASHTXBUF0-1614 32-bit (reset mask 0xFF) — Flash Transmit Buffer Register 0-16 (FLASHTXBUF0-16)
0x536 PBMRXBUF0-179 32-bit (reset mask 0xFF) — Peripheral Bus Master Receive Buffer Register 0-17 (PBMRXBUF0-17)
0x540 FLASHTXBUF0-1615 32-bit (reset mask 0xFF) — Flash Transmit Buffer Register 0-16 (FLASHTXBUF0-16)
0x540 PBMRXBUF0-1710 32-bit (reset mask 0xFF) — Peripheral Bus Master Receive Buffer Register 0-17 (PBMRXBUF0-17)
0x544 FLASHTXBUF0-1616 32-bit (reset mask 0xFF) — Flash Transmit Buffer Register 0-16 (FLASHTXBUF0-16)
0x544 PBMRXBUF0-1711 32-bit (reset mask 0xFF) — Peripheral Bus Master Receive Buffer Register 0-17 (PBMRXBUF0-17)
0x548 PBMRXBUF0-1712 32-bit (reset mask 0xFF) — Peripheral Bus Master Receive Buffer Register 0-17 (PBMRXBUF0-17)
0x552 PBMRXBUF0-1713 32-bit (reset mask 0xFF) — Peripheral Bus Master Receive Buffer Register 0-17 (PBMRXBUF0-17)
0x556 PBMRXBUF0-1714 32-bit (reset mask 0xFF) — Peripheral Bus Master Receive Buffer Register 0-17 (PBMRXBUF0-17)
0x560 PBMRXBUF0-1715 32-bit (reset mask 0xFF) — Peripheral Bus Master Receive Buffer Register 0-17 (PBMRXBUF0-17)
0x564 PBMRXBUF0-1716 32-bit (reset mask 0xFF) — Peripheral Bus Master Receive Buffer Register 0-17 (PBMRXBUF0-17)
0x568 PBMRXBUF0-1717 32-bit (reset mask 0xFF) — Peripheral Bus Master Receive Buffer Register 0-17 (PBMRXBUF0-17)
{0x2B0+4i} PBMTXBUF0-{i} 32-bit (reset mask 0xFF) (i=180..182) — Peripheral Bus Master Transmit Buffer Register 0-18 (PBMTXBUF0-18)
0x592 PBMTXBUF0-183 32-bit (reset mask 0xFF) — Peripheral Bus Master Transmit Buffer Register 0-18 (PBMTXBUF0-18)
0x596 PBMTXBUF0-184 32-bit (reset mask 0xFF) — Peripheral Bus Master Transmit Buffer Register 0-18 (PBMTXBUF0-18)
{0x31C+4i} PBMTXBUF0-{i} 32-bit (reset mask 0xFF) (i=185..187) — Peripheral Bus Master Transmit Buffer Register 0-18 (PBMTXBUF0-18)
{0x3A8+4i} FLASH_PRTR_BADDR0-{i} 32-bit (reset mask 0xFF) (i=150..152) — Flash Protection Range Base Address Register 0-15 (FLASH_PRTR_BADDR0-15)
  [31] SAF_PROT_LCK — Target-Attached Flash Protection Lock
  [30] FRNG_RPR — Flash Range Read Protect
  [29] FRNG_WPR — Flash Range Write Protect
  [26:12] FLASH_PRTR_BADDR — Flash Protection Base Address
0x612 PBMTXBUF0-188 32-bit (reset mask 0xFF) — Peripheral Bus Master Transmit Buffer Register 0-18 (PBMTXBUF0-18)
0x612 FLASH_PRTR_BADDR0-153 32-bit (reset mask 0xFF) — Flash Protection Range Base Address Register 0-15 (FLASH_PRTR_BADDR0-15)
  fields as FLASH_PRTR_BADDR0-150
0x616 PBMTXBUF0-189 32-bit (reset mask 0xFF) — Peripheral Bus Master Transmit Buffer Register 0-18 (PBMTXBUF0-18)
0x616 FLASH_PRTR_BADDR0-154 32-bit (reset mask 0xFF) — Flash Protection Range Base Address Register 0-15 (FLASH_PRTR_BADDR0-15)
  fields as FLASH_PRTR_BADDR0-150
0x620 PBMTXBUF0-1810 32-bit (reset mask 0xFF) — Peripheral Bus Master Transmit Buffer Register 0-18 (PBMTXBUF0-18)
{0x3B4+4i} FLASH_PRTR_BADDR0-{i} 32-bit (reset mask 0xFF) (i=155..157) — Flash Protection Range Base Address Register 0-15 (FLASH_PRTR_BADDR0-15)
  fields as FLASH_PRTR_BADDR0-150
0x624 PBMTXBUF0-1811 32-bit (reset mask 0xFF) — Peripheral Bus Master Transmit Buffer Register 0-18 (PBMTXBUF0-18)
0x628 PBMTXBUF0-1812 32-bit (reset mask 0xFF) — Peripheral Bus Master Transmit Buffer Register 0-18 (PBMTXBUF0-18)
0x632 PBMTXBUF0-1813 32-bit (reset mask 0xFF) — Peripheral Bus Master Transmit Buffer Register 0-18 (PBMTXBUF0-18)
0x632 FLASH_PRTR_BADDR0-158 32-bit (reset mask 0xFF) — Flash Protection Range Base Address Register 0-15 (FLASH_PRTR_BADDR0-15)
  fields as FLASH_PRTR_BADDR0-150
0x636 PBMTXBUF0-1814 32-bit (reset mask 0xFF) — Peripheral Bus Master Transmit Buffer Register 0-18 (PBMTXBUF0-18)
0x636 FLASH_PRTR_BADDR0-159 32-bit (reset mask 0xFF) — Flash Protection Range Base Address Register 0-15 (FLASH_PRTR_BADDR0-15)
  fields as FLASH_PRTR_BADDR0-150
0x640 PBMTXBUF0-1815 32-bit (reset mask 0xFF) — Peripheral Bus Master Transmit Buffer Register 0-18 (PBMTXBUF0-18)
0x640 FLASH_PRTR_BADDR0-1510 32-bit (reset mask 0xFF) — Flash Protection Range Base Address Register 0-15 (FLASH_PRTR_BADDR0-15)
  fields as FLASH_PRTR_BADDR0-150
{0x3E8+4i} FLASH_PRTR_TADDR0-{i} 32-bit (reset mask 0xFF) (i=150..152) — Flash Protection Range Top Address Register 0-15 (FLASH_PRTR_TADDR0-15)
  [26:12] FLASH_PRT_TADDR — Flash Protection Top Address
0x644 PBMTXBUF0-1816 32-bit (reset mask 0xFF) — Peripheral Bus Master Transmit Buffer Register 0-18 (PBMTXBUF0-18)
0x644 FLASH_PRTR_BADDR0-1511 32-bit (reset mask 0xFF) — Flash Protection Range Base Address Register 0-15 (FLASH_PRTR_BADDR0-15)
  fields as FLASH_PRTR_BADDR0-150
0x648 PBMTXBUF0-1817 32-bit (reset mask 0xFF) — Peripheral Bus Master Transmit Buffer Register 0-18 (PBMTXBUF0-18)
0x648 FLASH_PRTR_BADDR0-1512 32-bit (reset mask 0xFF) — Flash Protection Range Base Address Register 0-15 (FLASH_PRTR_BADDR0-15)
  fields as FLASH_PRTR_BADDR0-150
0x652 PBMTXBUF0-1818 32-bit (reset mask 0xFF) — Peripheral Bus Master Transmit Buffer Register 0-18 (PBMTXBUF0-18)
0x652 FLASH_PRTR_BADDR0-1513 32-bit (reset mask 0xFF) — Flash Protection Range Base Address Register 0-15 (FLASH_PRTR_BADDR0-15)
  fields as FLASH_PRTR_BADDR0-150
0x652 FLASH_PRTR_TADDR0-153 32-bit (reset mask 0xFF) — Flash Protection Range Top Address Register 0-15 (FLASH_PRTR_TADDR0-15)
  [26:12] FLASH_PRT_TADDR — Flash Protection Top Address
0x656 FLASH_PRTR_BADDR0-1514 32-bit (reset mask 0xFF) — Flash Protection Range Base Address Register 0-15 (FLASH_PRTR_BADDR0-15)
  fields as FLASH_PRTR_BADDR0-150
0x656 FLASH_PRTR_TADDR0-154 32-bit (reset mask 0xFF) — Flash Protection Range Top Address Register 0-15 (FLASH_PRTR_TADDR0-15)
  [26:12] FLASH_PRT_TADDR — Flash Protection Top Address
0x660 FLASH_PRTR_BADDR0-1515 32-bit (reset mask 0xFF) — Flash Protection Range Base Address Register 0-15 (FLASH_PRTR_BADDR0-15)
  fields as FLASH_PRTR_BADDR0-150
{0x3F4+4i} FLASH_PRTR_TADDR0-{i} 32-bit (reset mask 0xFF) (i=155..157) — Flash Protection Range Top Address Register 0-15 (FLASH_PRTR_TADDR0-15)
  [26:12] FLASH_PRT_TADDR — Flash Protection Top Address
0x672 FLASH_PRTR_TADDR0-158 32-bit (reset mask 0xFF) — Flash Protection Range Top Address Register 0-15 (FLASH_PRTR_TADDR0-15)
  [26:12] FLASH_PRT_TADDR — Flash Protection Top Address
0x676 FLASH_PRTR_TADDR0-159 32-bit (reset mask 0xFF) — Flash Protection Range Top Address Register 0-15 (FLASH_PRTR_TADDR0-15)
  [26:12] FLASH_PRT_TADDR — Flash Protection Top Address
0x680 FLASH_PRTR_TADDR0-1510 32-bit (reset mask 0xFF) — Flash Protection Range Top Address Register 0-15 (FLASH_PRTR_TADDR0-15)
  [26:12] FLASH_PRT_TADDR — Flash Protection Top Address
{0x428+4i} FLASH_RNG_TAG_OVR0-{i} 32-bit (reset mask 0xFF) (i=150..152) — Flash Range Tag Override Register 0-15 (FLASH_RNG_TAG_OVR0-15)
  [31:16] FRNG_RPR_TOVR — Flash Range Read Protect Tag Override
  [15:0] FRNG_WPR_TOVR — Flash Write Protect Tag Override
0x684 FLASH_PRTR_TADDR0-1511 32-bit (reset mask 0xFF) — Flash Protection Range Top Address Register 0-15 (FLASH_PRTR_TADDR0-15)
  [26:12] FLASH_PRT_TADDR — Flash Protection Top Address
0x688 FLASH_PRTR_TADDR0-1512 32-bit (reset mask 0xFF) — Flash Protection Range Top Address Register 0-15 (FLASH_PRTR_TADDR0-15)
  [26:12] FLASH_PRT_TADDR — Flash Protection Top Address
0x692 FLASH_PRTR_TADDR0-1513 32-bit (reset mask 0xFF) — Flash Protection Range Top Address Register 0-15 (FLASH_PRTR_TADDR0-15)
  [26:12] FLASH_PRT_TADDR — Flash Protection Top Address
0x692 FLASH_RNG_TAG_OVR0-153 32-bit (reset mask 0xFF) — Flash Range Tag Override Register 0-15 (FLASH_RNG_TAG_OVR0-15)
  fields as FLASH_RNG_TAG_OVR0-150
0x696 FLASH_PRTR_TADDR0-1514 32-bit (reset mask 0xFF) — Flash Protection Range Top Address Register 0-15 (FLASH_PRTR_TADDR0-15)
  [26:12] FLASH_PRT_TADDR — Flash Protection Top Address
0x696 FLASH_RNG_TAG_OVR0-154 32-bit (reset mask 0xFF) — Flash Range Tag Override Register 0-15 (FLASH_RNG_TAG_OVR0-15)
  fields as FLASH_RNG_TAG_OVR0-150
0x700 FLASH_PRTR_TADDR0-1515 32-bit (reset mask 0xFF) — Flash Protection Range Top Address Register 0-15 (FLASH_PRTR_TADDR0-15)
  [26:12] FLASH_PRT_TADDR — Flash Protection Top Address
{0x494+4i} FLASH_RNG_TAG_OVR0-{i} 32-bit (reset mask 0xFF) (i=155..157) — Flash Range Tag Override Register 0-15 (FLASH_RNG_TAG_OVR0-15)
  fields as FLASH_RNG_TAG_OVR0-150
0x712 FLASH_RNG_TAG_OVR0-158 32-bit (reset mask 0xFF) — Flash Range Tag Override Register 0-15 (FLASH_RNG_TAG_OVR0-15)
  fields as FLASH_RNG_TAG_OVR0-150
0x716 FLASH_RNG_TAG_OVR0-159 32-bit (reset mask 0xFF) — Flash Range Tag Override Register 0-15 (FLASH_RNG_TAG_OVR0-15)
  fields as FLASH_RNG_TAG_OVR0-150
0x720 FLASH_RNG_TAG_OVR0-1510 32-bit (reset mask 0xFF) — Flash Range Tag Override Register 0-15 (FLASH_RNG_TAG_OVR0-15)
  fields as FLASH_RNG_TAG_OVR0-150
0x724 FLASH_RNG_TAG_OVR0-1511 32-bit (reset mask 0xFF) — Flash Range Tag Override Register 0-15 (FLASH_RNG_TAG_OVR0-15)
  fields as FLASH_RNG_TAG_OVR0-150
0x728 FLASH_RNG_TAG_OVR0-1512 32-bit (reset mask 0xFF) — Flash Range Tag Override Register 0-15 (FLASH_RNG_TAG_OVR0-15)
  fields as FLASH_RNG_TAG_OVR0-150
0x732 FLASH_RNG_TAG_OVR0-1513 32-bit (reset mask 0xFF) — Flash Range Tag Override Register 0-15 (FLASH_RNG_TAG_OVR0-15)
  fields as FLASH_RNG_TAG_OVR0-150
0x736 FLASH_RNG_TAG_OVR0-1514 32-bit (reset mask 0xFF) — Flash Range Tag Override Register 0-15 (FLASH_RNG_TAG_OVR0-15)
  fields as FLASH_RNG_TAG_OVR0-150
0x740 FLASH_RNG_TAG_OVR0-1515 32-bit (reset mask 0xFF) — Flash Range Tag Override Register 0-15 (FLASH_RNG_TAG_OVR0-15)
  fields as FLASH_RNG_TAG_OVR0-150
0x800 FLASH_RPMC_CFG_1 32-bit (reset mask 0xFF) — Flash RPMC Configuration 1 Register (FLASH_RPMC_CFG_1)
  [31:26] TRGRPMCSUPP — Target RPMC Supported
  [25:24] RPMC_DEV_SUPP — Number of TAF RPMC Flash Devices Supported
  [23:16] RPMC_OP1_2 — RPMC OP1 Opcode on the 2nd RPMC Flash Device
  [15:12] RPMC_CNTR_2 — RPMC Counter on the 2nd RPMC Flash Device
  [11:4] RPMC_OP1_1 — RPMC OP1 Opcode on the 1st RPMC Flash Device
  [3:0] RPMC_CNTR_1 — RPMC Counter on the 1st RPMC Flash Device
0x804 FLASH_RPMC_CFG_2 32-bit (reset mask 0xFF) — Flash RPMC Configuration Register 2 (FLASH_RPMC_CFG_2)
  [23:16] RPMC_OP1_4 — RPMC OP1 Opcode on the 4th RPMC Flash Device
  [15:12] RPMC_CNTR_4 — RPMC Counter the 4th RPMC Flash Device
  [11:4] RPMC_OP1_3 — RPMC OP1 Opcode on the 3rd RPMC Flash Device
  [3:0] RPMC_CNTR_3 — RPMC Counter the 3rd RPMC Flash Device
0x808 RMAP_FLASH_OFFS 32-bit (reset mask 0xFF) — Remapping Flash Offset Register (RMAP_FLASH_OFFS)
  [26:0] RMAP_FLASH_OFFS — Remapping Flash Offset
0x80C RMAP_DST_BASE 32-bit (reset mask 0xFF) — Remapping Destination Base Register (RMAP_DST_BASE)
0x810 RMAP_WIN_SIZE 32-bit (reset mask 0xFF) — Remapping Window Size Register (RMAP_WIN_SIZE)
  [28:11] RMAP_WIN_SZ — Mapping Window Size
  [0] SAF_RMAP_LCK — Target-Attached Flash Remap Lock
0x814 FLASHBASE 32-bit (reset mask 0xFF) — Flash Base Register (FLASHBASE)
  [26:12] FLBASE_ADDR — Flash Base Address
  [0] FLBASE_LCK — FLASHBASE Lock
0x818 FLRLCK 32-bit (reset mask 0xFF) — Flash Reversible Lock Register (FLRLCK)
  [15:8] SAF_RMAP_RGLK — Target-Attached Flash Remap Reversible Global Lock
  [7:0] SAF_PROT_RGLK — Target-Attached Flash Protection Reversible Global Lock
{0x658+4i} PSMRXBUF0-{i} 32-bit (reset mask 0xFF) (i=170..172) — Peripheral Target Message Receive Buffer Register 0-17 (PSMRXBUF0-17)
0x912 PSMRXBUF0-173 32-bit (reset mask 0xFF) — Peripheral Target Message Receive Buffer Register 0-17 (PSMRXBUF0-17)
0x916 PSMRXBUF0-174 32-bit (reset mask 0xFF) — Peripheral Target Message Receive Buffer Register 0-17 (PSMRXBUF0-17)
{0x664+4i} PSMRXBUF0-{i} 32-bit (reset mask 0xFF) (i=175..177) — Peripheral Target Message Receive Buffer Register 0-17 (PSMRXBUF0-17)
0x932 PSMRXBUF0-178 32-bit (reset mask 0xFF) — Peripheral Target Message Receive Buffer Register 0-17 (PSMRXBUF0-17)
0x936 PSMRXBUF0-179 32-bit (reset mask 0xFF) — Peripheral Target Message Receive Buffer Register 0-17 (PSMRXBUF0-17)
0x940 PSMRXBUF0-1710 32-bit (reset mask 0xFF) — Peripheral Target Message Receive Buffer Register 0-17 (PSMRXBUF0-17)
0x944 PSMRXBUF0-1711 32-bit (reset mask 0xFF) — Peripheral Target Message Receive Buffer Register 0-17 (PSMRXBUF0-17)
0x948 PSMRXBUF0-1712 32-bit (reset mask 0xFF) — Peripheral Target Message Receive Buffer Register 0-17 (PSMRXBUF0-17)
0x952 PSMRXBUF0-1713 32-bit (reset mask 0xFF) — Peripheral Target Message Receive Buffer Register 0-17 (PSMRXBUF0-17)
0x956 PSMRXBUF0-1714 32-bit (reset mask 0xFF) — Peripheral Target Message Receive Buffer Register 0-17 (PSMRXBUF0-17)
0x960 PSMRXBUF0-1715 32-bit (reset mask 0xFF) — Peripheral Target Message Receive Buffer Register 0-17 (PSMRXBUF0-17)
0x964 PSMRXBUF0-1716 32-bit (reset mask 0xFF) — Peripheral Target Message Receive Buffer Register 0-17 (PSMRXBUF0-17)
0x968 PSMRXBUF0-1717 32-bit (reset mask 0xFF) — Peripheral Target Message Receive Buffer Register 0-17 (PSMRXBUF0-17)
